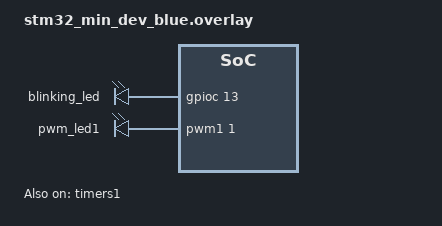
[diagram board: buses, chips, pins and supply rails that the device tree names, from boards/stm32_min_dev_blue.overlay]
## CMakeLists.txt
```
cmake_minimum_required(VERSION 3.22)
set(BOARD stm32_min_dev@blue)

find_package(Zephyr)
project(Blink_portable)

target_sources(app PRIVATE src/main.c)
```

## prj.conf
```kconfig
CONFIG_PRINTK=y
CONFIG_PWM=y
CONFIG_PWM_STM32=y
```

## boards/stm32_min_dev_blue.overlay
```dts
/   {
        leds {
            compatible = "gpio-leds";
            blinking_led: blinking_led {
            gpios = <&gpioc 13 GPIO_ACTIVE_HIGH>;
            };
        };

        pwmleds: pwmleds {
		compatible = "pwm-leds";
		status = "okay";
		pwm_led1: pwm_led1 {
				pwms = <&pwm1 1 PWM_MSEC(20) PWM_POLARITY_NORMAL>;
			};
		};
	};


&timers1 {
	st,prescaler = <10000>;
	status = "okay";
};
```

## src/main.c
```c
#include <zephyr/kernel.h>
#include <zephyr/sys/printk.h>
#include <zephyr/device.h>
#include <zephyr/drivers/pwm.h>

static const struct pwm_dt_spec pwm_led = PWM_DT_SPEC_GET(DT_NODELABEL(pwm_led1));

#define PERIOD PWM_MSEC(500U)
#define PULSE PERIOD / 4U

int main(void)
{
	int ret;

	printk("PWM-based blinky\n");

	if (!pwm_is_ready_dt(&pwm_led)) {
		printk("Error: PWM device %s is not ready\n", pwm_led.dev->name);
		return 0;
	}
	
	//Set the pwm period and pulse.
	ret = pwm_set_dt(&pwm_led, PERIOD, PULSE);

	if (ret) {
		printk("Error %d: failed to set pulse width\n", ret);
		return 0;
	}

	while (1) {
		printk("Inside Loop\n");
		k_sleep(K_SECONDS(1U));
	}

	return 0;
}
```
